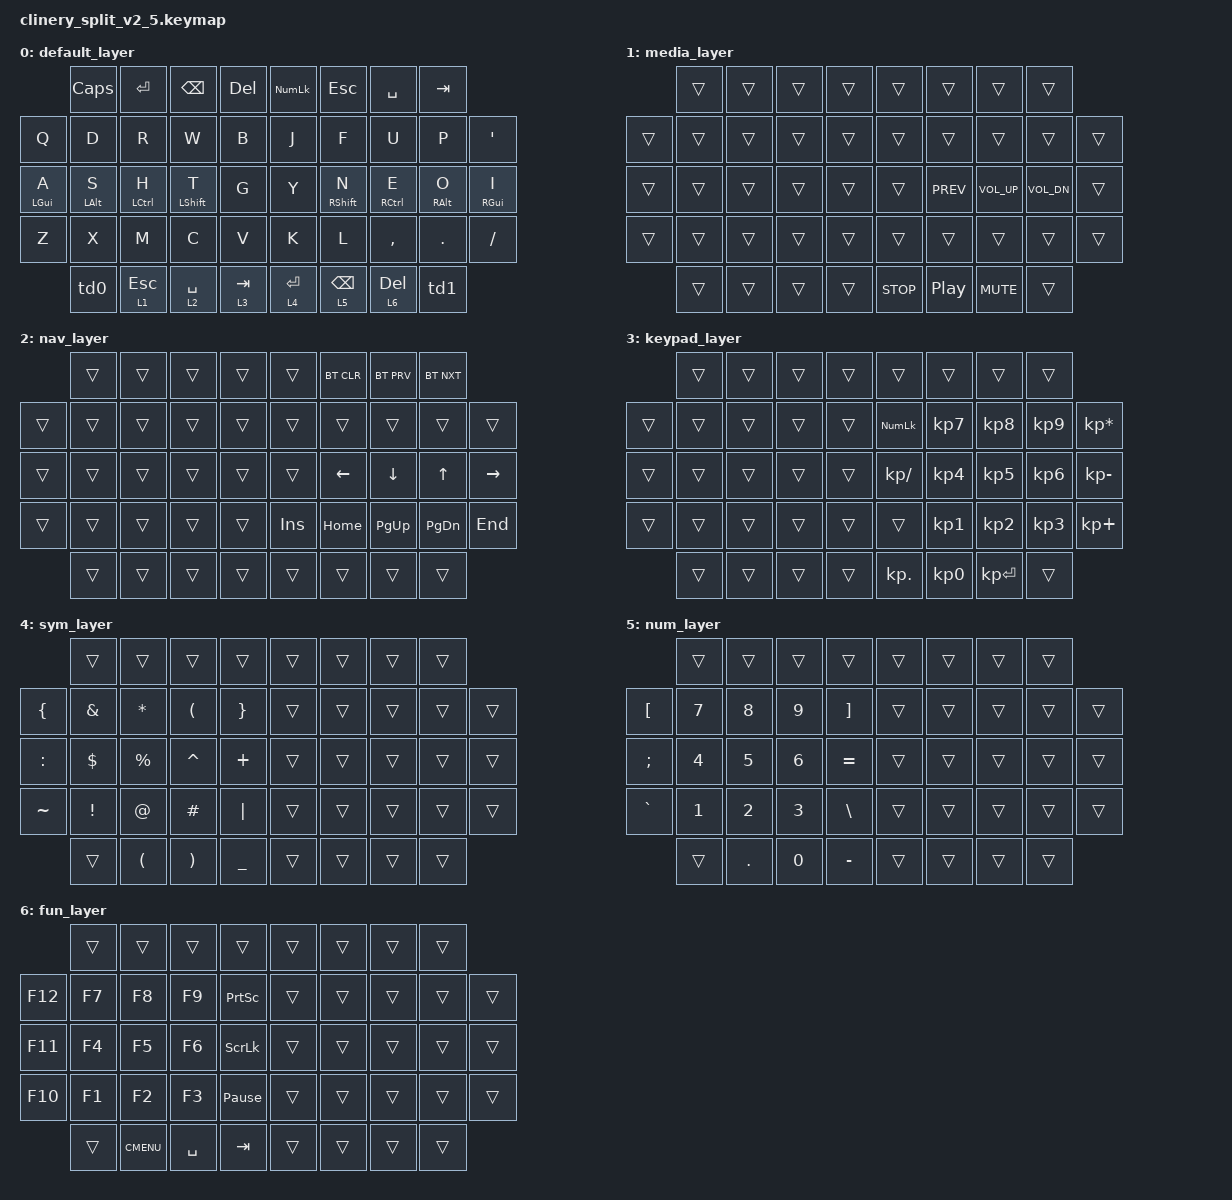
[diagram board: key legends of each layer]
#include <behaviors.dtsi>
#include <dt-bindings/zmk/keys.h>
#include <dt-bindings/zmk/bt.h>

&soft_off {
    hold-time-ms = <5000>; // Only turn off if the key is held for 5 seconds or longer.
};

&mt {
    tapping-term-ms = <180>;
    quick-tap-ms = <180>;
    require-prior-idle-ms = <150>;
    flavor = "tap-preferred";
};

&lt {
    tapping-term-ms = <180>;
    quick-tap-ms = <180>;
    flavor = "tap-preferred";
};

/ {
    behaviors {
        td0: tap_dance_0 {
            compatible = "zmk,behavior-tap-dance";
            #binding-cells = <0>;
            tapping-term-ms = <200>;
            bindings = <&soft_off>, <&bt BT_SEL 0>, <&bt BT_SEL 1>, <&bt BT_SEL 2>;
        };
        td1: tap_dance_1 {
            compatible = "zmk,behavior-tap-dance";
            #binding-cells = <0>;
            tapping-term-ms = <200>;
            bindings = <&none>, <&bt BT_DISC 0>, <&bt BT_DISC 1>, <&bt BT_DISC 2>;
        };
    };

    keymap {
        compatible = "zmk,keymap";

        default_layer { // Layer 0
            //
            // Miryoku-base
            //       ,-----------------------.             ,-----------------------.
            //       |Caps |Enter|Back | Del |             |NumLk| Esc |Space| Tab |
            // ,-----+-----+-----+-----+-----|             |-----+-----+-----+-----+-----.
            // |  Q  |  D  |  R  |  W  |  B  |             |  J  |  F  |  U  |  P  |  '  |
            // |-----+-----+-----+-----+-----|             |-----+-----+-----+-----+-----|
            // |  A  |  S  |  H  |  T  |  G  |             |  Y  |  N  |  E  |  O  |  I  |
            // |-----+-----+-----+-----+-----|             |-----+-----+-----+-----+-----|
            // |  Z  |  X  |  M  |  C  |  V  |             |  K  |  L  |  ,  |  .  |  /  |
            // `-----------------------------^-.         .-^-----------------------------'
            //         |MODE | Esc |Space| Tab |         |Enter|Back | Del |MODE |
            //         `-----------------------'         `-----------------------'
            //
            bindings = <
                            &kp CAPS    &kp ENTER    &kp BSPC     &kp DELETE     &kp KP_NUM   &kp ESCAPE   &kp SPACE    &kp TAB
                &kp Q       &kp D       &kp R        &kp W        &kp B          &kp J        &kp F        &kp U        &kp P       &kp SQT
                &mt LGUI A  &mt LALT S  &mt LCTRL H  &mt LSHFT T  &kp G          &kp Y        &mt RSHFT N  &mt RCTRL E  &mt RALT O  &mt RGUI I
                &kp Z       &kp X       &kp M        &kp C        &kp V          &kp K        &kp L        &kp COMMA    &kp DOT     &kp SLASH
                            &td0        &lt 1 ESCAPE &lt 2 SPACE  &lt 3 TAB      &lt 4 ENTER  &lt 5 BSPC   &lt 6 DELETE &td1
            >;
        };
        media_layer { // Layer 1
            //
            //       ,-----------------------.             ,-----------------------.
            //       |     |     |     |     |             |     |     |     |     |
            // ,-----+-----+-----+-----+-----|             |-----+-----+-----+-----+-----.
            // |     |     |     |     |     |             |     |     |     |     |     |
            // |-----+-----+-----+-----+-----|             |-----+-----+-----+-----+-----|
            // |     |     |     |     |     |             |     |Prev |VolD |VolU |Next |
            // |-----+-----+-----+-----+-----|             |-----+-----+-----+-----+-----|
            // |     |     |     |     |     |             |     |     |     |     |     |
            // `-----------------------------^-.         .-^-----------------------------'
            //         |     |     |     |     |         |Stop |Play |Mute |     |
            //         `-----------------------'         '-----------------------'
            //
            bindings = <
                            &trans      &trans       &trans       &trans         &trans       &trans       &trans       &trans
                &trans      &trans      &trans       &trans       &trans         &trans       &trans       &trans       &trans       &trans
                &trans      &trans      &trans       &trans       &trans         &trans       &kp C_PREV   &kp C_VOL_UP &kp C_VOL_DN &trans
                &trans      &trans      &trans       &trans       &trans         &trans       &trans       &trans       &trans       &trans
                            &trans      &trans       &trans       &trans         &kp C_STOP   &kp C_PP     &kp C_MUTE   &trans
            >;
        };
        nav_layer { // Layer 2
            //
            //       ,-----------------------.             ,-----------------------.
            //       |     |     |     |     |             |     |BTCLR|BTPRV|BTNXT|
            // ,-----+-----+-----+-----+-----|             |-----+-----+-----+-----+-----.
            // |     |     |     |     |     |             |     |     |     |     |     |
            // |-----+-----+-----+-----+-----|             |-----+-----+-----+-----+-----|
            // |     |     |     |     |     |             |     |Left |Down | Up  |Right|
            // |-----+-----+-----+-----+-----|             |-----+-----+-----+-----+-----|
            // |     |     |     |     |     |             |Inser|Home |PgDn |PgUp |End  |
            // `-----------------------------^-.         .-^-----------------------------'
            //         |     |     |     |     |         |     |     |     |     |
            //         `-----------------------'         '-----------------------'
            //
            bindings = <
                            &trans      &trans       &trans       &trans         &trans       &bt BT_CLR   &bt BT_PRV   &bt BT_NXT
                &trans      &trans      &trans       &trans       &trans         &trans       &trans       &trans       &trans       &trans
                &trans      &trans      &trans       &trans       &trans         &trans       &kp LEFT     &kp DOWN     &kp UP       &kp RIGHT
                &trans      &trans      &trans       &trans       &trans         &kp INSERT   &kp HOME     &kp PG_UP    &kp PG_DN    &kp END
                            &trans      &trans       &trans       &trans         &trans       &trans       &trans       &trans
            >;
        };
        keypad_layer { // Layer 3
            //
            //       ,-----------------------.             ,-----------------------.
            //       |     |     |     |     |             |     |     |     |     |
            // ,-----+-----+-----+-----+-----|             |-----+-----+-----+-----+-----.
            // |     |     |     |     |     |             |N LCK|  7  |  8  |  9  |  *  |
            // |-----+-----+-----+-----+-----|             |-----+-----+-----+-----+-----|
            // |     |     |     |     |     |             |  /  |  4  |  5  |  6  |  -  |
            // |-----+-----+-----+-----+-----|             |-----+-----+-----+-----+-----|
            // |     |     |     |     |     |             |     |  1  |  2  |  3  |  +  |
            // `-----------------------------^-.         .-^-----------------------------'
            //         |     |     |     |     |         |  .  |  0  |Enter|     |
            //         `-----------------------'         '-----------------------'
            //
            bindings = <
                            &trans      &trans       &trans       &trans         &trans       &trans       &trans       &trans
                &trans      &trans      &trans       &trans       &trans         &kp KP_NUM   &kp KP_N7    &kp KP_N8    &kp KP_N9    &kp KP_MULTIPLY
                &trans      &trans      &trans       &trans       &trans         &kp KP_SLASH &kp KP_N4    &kp KP_N5    &kp KP_N6    &kp KP_MINUS
                &trans      &trans      &trans       &trans       &trans         &trans       &kp KP_N1    &kp KP_N2    &kp KP_N3    &kp KP_PLUS
                            &trans      &trans       &trans       &trans         &kp KP_DOT   &kp KP_N0    &kp KP_ENTER &trans
            >;
        };
        sym_layer { // Layer 4
            //
            //       ,-----------------------.             ,-----------------------.
            //       |     |     |     |     |             |     |     |     |     |
            // ,-----+-----+-----+-----+-----|             |-----+-----+-----+-----+-----.
            // |  {  |  &  |  *  |  (  |  }  |             |     |     |     |     |     |
            // |-----+-----+-----+-----+-----|             |-----+-----+-----+-----+-----|
            // |  :  |  $  |  %  |  ^  |  +  |             |     |     |     |     |     |
            // |-----+-----+-----+-----+-----|             |-----+-----+-----+-----+-----|
            // |  ~  |  !  |  @  |  #  |  |  |             |     |     |     |     |     |
            // `-----------------------------^-.         .-^-----------------------------'
            //         |     |  (  |  )  |  _  |         |     |     |     |     |
            //         `-----------------------'         '-----------------------'
            //
            bindings = <
                            &trans      &trans       &trans       &trans         &trans       &trans       &trans       &trans
                &kp LBRC    &kp AMPS    &kp STAR     &kp LPAR     &kp RBRC       &trans       &trans       &trans       &trans       &trans
                &kp COLON   &kp DOLLAR  &kp PERCENT  &kp CARET    &kp PLUS       &trans       &trans       &trans       &trans       &trans
                &kp TILDE   &kp EXCL    &kp AT       &kp HASH     &kp PIPE       &trans       &trans       &trans       &trans       &trans
                            &trans      &kp LPAR     &kp RPAR     &kp UNDER      &trans       &trans       &trans       &trans
            >;
        };
        num_layer { // Layer 5
            //  number uses
            //       ,-----------------------.             ,-----------------------.
            //       |     |     |     |     |             |     |     |     |     |
            // ,-----+-----+-----+-----+-----|             |-----+-----+-----+-----+-----.
            // |  [  |  7  |  8  |  9  |  ]  |             |     |     |     |     |     |
            // |-----+-----+-----+-----+-----|             |-----+-----+-----+-----+-----|
            // |  ;  |  4  |  5  |  7  |  =  |             |     |     |     |     |     |
            // |-----+-----+-----+-----+-----|             |-----+-----+-----+-----+-----|
            // |  `  |  1  |  2  |  3  |  \  |             |     |     |     |     |     |
            // `-----------------------------^-.         .-^-----------------------------'
            //         |     |  .  |  0  |  -  |         |     |     |     |     |
            //         `-----------------------'         '-----------------------'
            //
            bindings = <
                            &trans      &trans       &trans       &trans         &trans       &trans       &trans       &trans
                &kp LBKT    &kp N7      &kp N8       &kp N9       &kp RBKT       &trans       &trans       &trans       &trans       &trans
                &kp SEMI    &kp N4      &kp N5       &kp N6       &kp EQUAL      &trans       &trans       &trans       &trans       &trans
                &kp GRAVE   &kp N1      &kp N2       &kp N3       &kp BACKSLASH  &trans       &trans       &trans       &trans       &trans
                            &trans      &kp DOT      &kp N0       &kp MINUS      &trans       &trans       &trans       &trans
            >;
        };
        fun_layer { // Layer 6
            //
            //       ,-----------------------.             ,-----------------------.
            //       |BT 0 |BT 1 |BT 2 |BT 3 |             |     |     |     |     |
            // ,-----+-----+-----+-----+-----|             |-----+-----+-----+-----+-----.
            // | F12 | F7  | F8  | F9  |PrntS|             |     |     |     |     |     |
            // |-----+-----+-----+-----+-----|             |-----+-----+-----+-----+-----|
            // | F11 | F4  | F5  | F6  |SclLk|             |     |     |     |     |     |
            // |-----+-----+-----+-----+-----|             |-----+-----+-----+-----+-----|
            // | F10 | F1  | F2  | F3  |PauBr|             |     |     |     |     |     |
            // `-----------------------------^-.         .-^-----------------------------'
            //         |     |Menu |Space| Tab |         |     |     |     |     |
            //         `-----------------------'         '-----------------------'
            //
            bindings = <
                            &trans      &trans       &trans       &trans         &trans       &trans       &trans       &trans
                &kp F12     &kp F7      &kp F8       &kp F9       &kp PSCRN      &trans       &trans       &trans       &trans       &trans
                &kp F11     &kp F4      &kp F5       &kp F6       &kp SLCK       &trans       &trans       &trans       &trans       &trans
                &kp F10     &kp F1      &kp F2       &kp F3       &kp PAUSE_BREAK&trans       &trans       &trans       &trans       &trans
                            &trans      &kp K_CMENU  &kp SPACE    &kp TAB        &trans       &trans       &trans       &trans
            >;
        };
    };
};

// vim: textwidth=0
